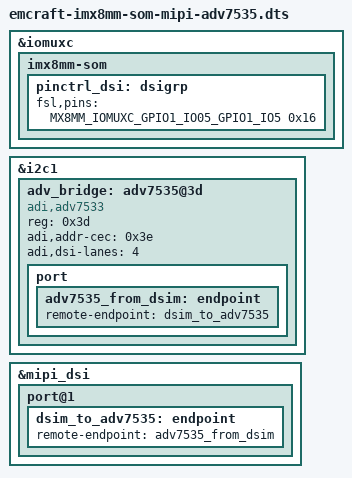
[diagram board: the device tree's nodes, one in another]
/*
 * Copyright 2019 Emcraft Systems
 *
 * This program is free software; you can redistribute it and/or
 * modify it under the terms of the GNU General Public License
 * as published by the Free Software Foundation; either version 2
 * of the License, or (at your option) any later version.
 *
 * This program is distributed in the hope that it will be useful,
 * but WITHOUT ANY WARRANTY; without even the implied warranty of
 * MERCHANTABILITY or FITNESS FOR A PARTICULAR PURPOSE.  See the
 * GNU General Public License for more details.
 */

#include "emcraft-imx8mm-som.dts"

&iomuxc {
	pinctrl-names = "default";

	imx8mm-som {
		pinctrl_dsi: dsigrp {
			fsl,pins = <
				MX8MM_IOMUXC_GPIO1_IO05_GPIO1_IO5		0x16
			>;
		};
	};
};

&i2c1 {
	adv_bridge: adv7535@3d {
		compatible = "adi,adv7533";
		reg = <0x3d>;
		adi,addr-cec = <0x3e>;
		adi,dsi-lanes = <4>;
		status = "okay";

		port {
			adv7535_from_dsim: endpoint {
				remote-endpoint = <&dsim_to_adv7535>;
			};
		};
	};
};

&mipi_dsi {
	status = "okay";

	port@1 {
		dsim_to_adv7535: endpoint {
			remote-endpoint = <&adv7535_from_dsim>;
		};
	};
};
